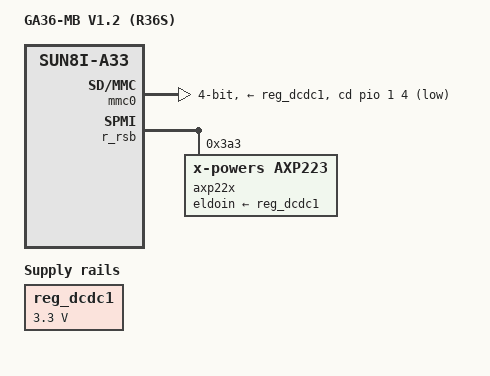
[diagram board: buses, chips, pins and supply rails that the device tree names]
/*
 * GA36-MB V1.2 (R36S) — U-Boot board device tree
 *
 * U-Boot-only tree (target: U-Boot 2025.07 arch/arm/dts/sun8i-a33-ga36-mb-v1.2.dts).
 * U-Boot does not boot the kernel from this tree: bootz loads the kernel's own
 * /boot/sun8i-a33-ga36-mb-v1.2.dtb from the SD boot partition. This tree only
 * has to describe enough for U-Boot itself: console, MMC (boot device), PMIC
 * (rail setup) and USB PHY (OTG ID).
 *
 * Pins/rails are the fex values (see output/hardware-report.md):
 *   uart_debug_port=2 (PB00/PB01), sdc_det=PB04, sdc_power=axp22_dcdc1,
 *   s_rsb PL00/PL01 + axp223, usb_id_gpio=PH08.
 */

/dts-v1/;
#include "sun8i-a33.dtsi"

#include <dt-bindings/gpio/gpio.h>

/ {
	model = "GA36-MB V1.2 (R36S)";
	compatible = "ga36-mb-v1.2","allwinner,sun8i-a33";

	aliases {
		serial2 = &uart2;
	};

	chosen {
		stdout-path = "serial2:115200n8";
	};
};

&mmc0 {
	bus-width = <4>;
	cd-gpios = <&pio 1 4 GPIO_ACTIVE_LOW>; /* PB04 */
	vmmc-supply = <&reg_dcdc1>;
};

&r_rsb {
	status = "okay";

	axp22x: pmic@3a3 {
		compatible = "x-powers,axp223";
		reg = <0x3a3>;
		eldoin-supply = <&reg_dcdc1>;
		x-powers,drive-vbus-en;
	};
};

#include "axp223.dtsi"

&reg_dcdc1 {
	regulator-always-on;
	regulator-min-microvolt = <3300000>;
	regulator-max-microvolt = <3300000>;
};

&usbphy {
	usb0_id_det-gpios = <&pio 1 8 GPIO_ACTIVE_HIGH>; /* PH08 */
	usb0_vbus_power-supply = <&usb_power_supply>;
	usb0_vbus-supply = <&reg_drivevbus>;
};
